AUTOSAR XML (schema 4-2-2)
package /CDD_CORE4
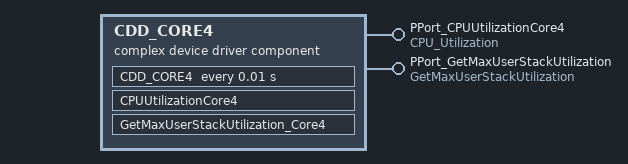
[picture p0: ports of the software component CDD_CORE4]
  complex device driver sw component type CDD_CORE4
    provide port PPort_CPUUtilizationCore4: provided-interface=CPU_Utilization
    provide port PPort_GetMaxUserStackUtilization: provided-interface=GetMaxUserStackUtilization
    behavior SwcInternalBehavior
      operation invoked event OperationInvokedEvent_0: start-on-event=CPUUtilizationCore4, operation=PPort_CPUUtilizationCore4.CPU_Utilization
      timing event TimingEvent_0: start-on-event=CDD_CORE4, period=0.01
      operation invoked event OperationInvokedEvent_1: start-on-event=GetMaxUserStackUtilization_Core4, operation=PPort_GetMaxUserStackUtilization.GetMaxUserStackUtilization
      runnable CPUUtilizationCore4: symbol=CPUUtilizationCore4_func
      runnable CDD_CORE4: symbol=CDD_CORE4_func
      runnable GetMaxUserStackUtilization_Core4: symbol=GetMaxUserStackUtilization_Core4_func
